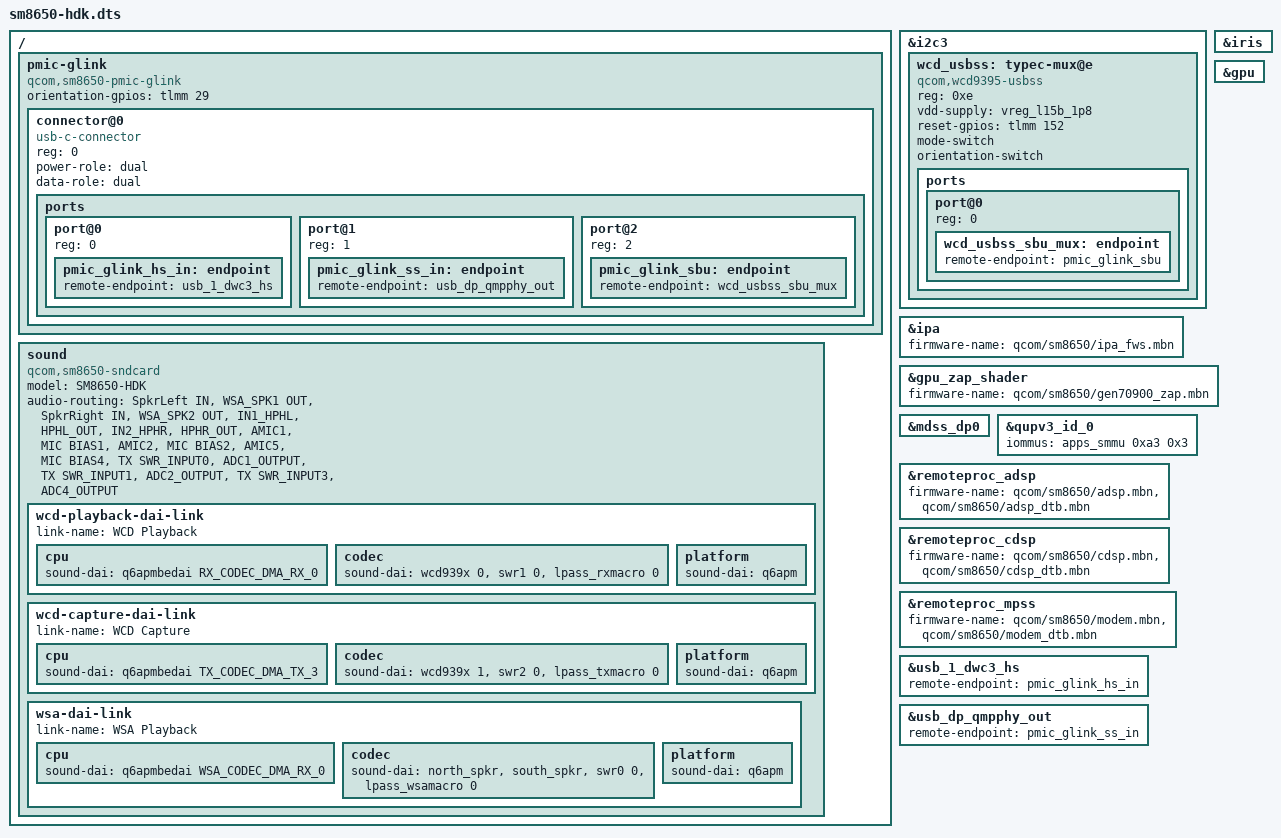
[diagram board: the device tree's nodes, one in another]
// SPDX-License-Identifier: BSD-3-Clause
/*
 * Copyright (c) 2024, Linaro Limited
 */

/dts-v1/;

#include "sm8650.dtsi"
#include "sm8650-hdk.dtsi"
#include "sm8650-el1.dtsi"

/ {
	pmic-glink {
		compatible = "qcom,sm8650-pmic-glink",
			     "qcom,sm8550-pmic-glink",
			     "qcom,pmic-glink";
		#address-cells = <1>;
		#size-cells = <0>;
		orientation-gpios = <&tlmm 29 GPIO_ACTIVE_HIGH>;

		connector@0 {
			compatible = "usb-c-connector";
			reg = <0>;

			power-role = "dual";
			data-role = "dual";

			ports {
				#address-cells = <1>;
				#size-cells = <0>;

				port@0 {
					reg = <0>;

					pmic_glink_hs_in: endpoint {
						remote-endpoint = <&usb_1_dwc3_hs>;
					};
				};

				port@1 {
					reg = <1>;

					pmic_glink_ss_in: endpoint {
						remote-endpoint = <&usb_dp_qmpphy_out>;
					};
				};

				port@2 {
					reg = <2>;

					pmic_glink_sbu: endpoint {
						remote-endpoint = <&wcd_usbss_sbu_mux>;
					};
				};
			};
		};
	};

	sound {
		compatible = "qcom,sm8650-sndcard", "qcom,sm8450-sndcard";
		model = "SM8650-HDK";
		audio-routing = "SpkrLeft IN", "WSA_SPK1 OUT",
				"SpkrRight IN", "WSA_SPK2 OUT",
				"IN1_HPHL", "HPHL_OUT",
				"IN2_HPHR", "HPHR_OUT",
				"AMIC1", "MIC BIAS1",
				"AMIC2", "MIC BIAS2",
				"AMIC5", "MIC BIAS4",
				"TX SWR_INPUT0", "ADC1_OUTPUT",
				"TX SWR_INPUT1", "ADC2_OUTPUT",
				"TX SWR_INPUT3", "ADC4_OUTPUT";

		wcd-playback-dai-link {
			link-name = "WCD Playback";

			cpu {
				sound-dai = <&q6apmbedai RX_CODEC_DMA_RX_0>;
			};

			codec {
				sound-dai = <&wcd939x 0>, <&swr1 0>, <&lpass_rxmacro 0>;
			};

			platform {
				sound-dai = <&q6apm>;
			};
		};

		wcd-capture-dai-link {
			link-name = "WCD Capture";

			cpu {
				sound-dai = <&q6apmbedai TX_CODEC_DMA_TX_3>;
			};

			codec {
				sound-dai = <&wcd939x 1>, <&swr2 0>, <&lpass_txmacro 0>;
			};

			platform {
				sound-dai = <&q6apm>;
			};
		};

		wsa-dai-link {
			link-name = "WSA Playback";

			cpu {
				sound-dai = <&q6apmbedai WSA_CODEC_DMA_RX_0>;
			};

			codec {
				sound-dai = <&north_spkr>, <&south_spkr>, <&swr0 0>, <&lpass_wsamacro 0>;
			};

			platform {
				sound-dai = <&q6apm>;
			};
		};
	};
};

&i2c3 {
	wcd_usbss: typec-mux@e {
		compatible = "qcom,wcd9395-usbss", "qcom,wcd9390-usbss";
		reg = <0xe>;

		vdd-supply = <&vreg_l15b_1p8>;
		reset-gpios = <&tlmm 152 GPIO_ACTIVE_HIGH>;

		mode-switch;
		orientation-switch;

		ports {
			#address-cells = <1>;
			#size-cells = <0>;

			port@0 {
				reg = <0>;

				wcd_usbss_sbu_mux: endpoint {
					remote-endpoint = <&pmic_glink_sbu>;
				};
			};
		};
	};
};

&ipa {
	firmware-name = "qcom/sm8650/ipa_fws.mbn";

	status = "okay";
};

&iris {
	status = "okay";
};

&gpu {
	status = "okay";
};

&gpu_zap_shader {
	firmware-name = "qcom/sm8650/gen70900_zap.mbn";
};

&mdss_dp0 {
	status = "okay";
};

&qupv3_id_0 {
	iommus = <&apps_smmu 0xa3 0x3>;
};

&remoteproc_adsp {
	firmware-name = "qcom/sm8650/adsp.mbn",
			"qcom/sm8650/adsp_dtb.mbn";

	status = "okay";
};

&remoteproc_cdsp {
	firmware-name = "qcom/sm8650/cdsp.mbn",
			"qcom/sm8650/cdsp_dtb.mbn";

	status = "okay";
};

&remoteproc_mpss {
	firmware-name = "qcom/sm8650/modem.mbn",
			"qcom/sm8650/modem_dtb.mbn";

	status = "okay";
};

&usb_1_dwc3_hs {
	remote-endpoint = <&pmic_glink_hs_in>;
};

&usb_dp_qmpphy_out {
	remote-endpoint = <&pmic_glink_ss_in>;
};
